# cbass_CBASS_ISC_45820000h register map
Vendor: Texas Instruments
Peripheral module from a debugger description file (folder am62D).
Registers are 32-bit, read-write, reset 0x0 unless marked. A register's access mark holds for its fields unless they carry their own. Offsets are as the file gives them; lines under a group give offsets from that group; [hi:lo] are bit positions; {n}, {i} and the like mark numbered series; 'fields as' and 'values as' point back to an identical list; <NAME> marks a mode.

## cbass_isc (part 1 of 2)
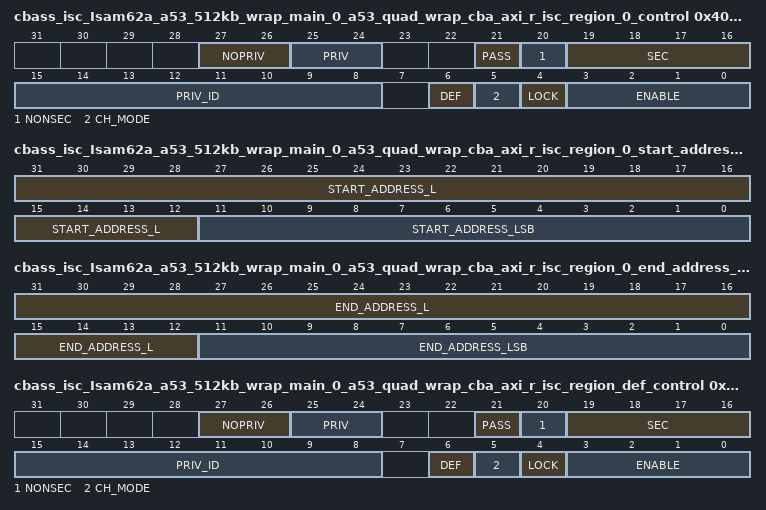
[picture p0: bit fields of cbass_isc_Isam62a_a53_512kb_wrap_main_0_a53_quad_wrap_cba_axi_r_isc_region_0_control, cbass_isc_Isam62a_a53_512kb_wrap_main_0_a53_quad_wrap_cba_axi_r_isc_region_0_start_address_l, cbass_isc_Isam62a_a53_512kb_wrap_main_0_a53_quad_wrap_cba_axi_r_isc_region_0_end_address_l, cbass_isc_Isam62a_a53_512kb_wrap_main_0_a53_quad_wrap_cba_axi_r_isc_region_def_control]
0x400 cbass_isc_Isam62a_a53_512kb_wrap_main_0_a53_quad_wrap_cba_axi_r_isc_region_0_control access not given reset 0x400 — The ISC Region 0 Control Register defines the control fields for the master Isam62a_a53_512kb_wrap_main_0.a53_quad_wrap_cba_axi_r region 0 ISC.
  [27:26] NOPRIV rw — Clear output priv attribute. If each bit is set then the outgoing priv bit is cleared. Reset Source: domain_default_rst_mod_g_rst_n
  [25:24] PRIV rw — Set outgoing priv attribute. If each bit is set then the outgoing priv bit is set. Reset Source: domain_default_rst_mod_g_rst_n
  [21] PASS rw — No privID replacement, pass through value. Reset Source: domain_default_rst_mod_g_rst_n
  [20] NONSEC rw — Make outgoing non-secure. Reset Source: domain_default_rst_mod_g_rst_n
  [19:16] SEC rw — Make outgoing secure. A value of 0xA enables, others disable. Reset Source: domain_default_rst_mod_g_rst_n
  [15:8] PRIV_ID rw — Priv ID. Reset Source: domain_default_rst_mod_g_rst_n
  [6] DEF ro — Default region indication. The default region is used when all other regions do not match. Reset Source: domain_default_rst_mod_g_rst_n
  [5] CH_MODE rw — Enable channel mode to match region to a chanid value. Otherwise use address mode to match region to an address range. Reset Source: domain_default_rst_mod_g_rst_n
  [4] LOCK — Lock region. Once set the region values cannot be modified. Reset Source: domain_default_rst_mod_g_rst_n (access R/W1TS)
  [3:0] ENABLE rw — Enable region. A value of 0xA enables, others disable. Reset Source: domain_default_rst_mod_g_rst_n
0x410 cbass_isc_Isam62a_a53_512kb_wrap_main_0_a53_quad_wrap_cba_axi_r_isc_region_0_start_address_l — The ISC Region 0 Start Address Low Register defines the start address bits 31 to 0 for the master Isam62a_a53_512kb_wrap_main_0.a53_quad_wrap_cba_axi_r region 0 ISC.
  [31:12] START_ADDRESS_L — Start address bits 31 to 12. Reset Source: domain_default_rst_mod_g_rst_n
  [11:0] START_ADDRESS_LSB — Start address bits 11 to 0 must be 0 as address must be 4KB aligned in address mode. Can also be channel number in channel mode. Reset Source: domain_default_rst_mod_g_rst_n
0x414 cbass_isc_Isam62a_a53_512kb_wrap_main_0_a53_quad_wrap_cba_axi_r_isc_region_0_start_address_h — The ISC Region 0 Start Address High Register defines the start address bits 47 to 32 for the master Isam62a_a53_512kb_wrap_main_0.a53_quad_wrap_cba_axi_r region 0 ISC.
  [15:0] START_ADDRESS_H — Start address bits 47 to 32. Reset Source: domain_default_rst_mod_g_rst_n
0x418 cbass_isc_Isam62a_a53_512kb_wrap_main_0_a53_quad_wrap_cba_axi_r_isc_region_0_end_address_l access per field reset 0xFFF — The ISC Region 0 End Address Low Register defines the end included address bits 31 to 0 for the master Isam62a_a53_512kb_wrap_main_0.a53_quad_wrap_cba_axi_r region 0 ISC.
  [31:12] END_ADDRESS_L rw — End address bits 31 to 12 to include in the match. Reset Source: domain_default_rst_mod_g_rst_n
  [11:0] END_ADDRESS_LSB ro — End address bits 11 to 0 are forced to Fs as address must be 4KB aligned. Reset Source: domain_default_rst_mod_g_rst_n
0x41C cbass_isc_Isam62a_a53_512kb_wrap_main_0_a53_quad_wrap_cba_axi_r_isc_region_0_end_address_h — The ISC Region 0 End Address High Register defines the end address bits 47 to 32 for the master Isam62a_a53_512kb_wrap_main_0.a53_quad_wrap_cba_axi_r region 0 ISC.
  [15:0] END_ADDRESS_H — End address bits 47 to 32. Reset Source: domain_default_rst_mod_g_rst_n
0x420 cbass_isc_Isam62a_a53_512kb_wrap_main_0_a53_quad_wrap_cba_axi_r_isc_region_def_control access not given reset 0x44A — The ISC Default Region Control Register defines the control fields for the master Isam62a_a53_512kb_wrap_main_0.a53_quad_wrap_cba_axi_r region 1 ISC.
  [27:26] NOPRIV rw — Clear output priv attribute. If each bit is set then the outgoing priv bit is cleared, else the bit is unchanged. Do not set both priv and nopriv for the same bit. Reset Source: domain_default_rst_mod_g_rst_n
  [25:24] PRIV rw — Set outgoing priv attribute. If each bit is set then the outgoing priv bit is set, else the bit is unchanged. Do not set both priv and nopriv for the same bit. Reset Source: domain_default_rst_mod_g_rst_n
  [21] PASS rw — No privID replacement. A value of 1 will pass through privid value. A value of 0 will replace privid with priv_id field value. Reset Source: domain_default_rst_mod_g_rst_n
  [20] NONSEC rw — Make outgoing non-secure. A value of 1 forces secure clear, others do nothing. Do not set both sec and nonsec. Reset Source: domain_default_rst_mod_g_rst_n
  [19:16] SEC rw — Make outgoing secure. A value of 0xA forces secure set, others do nothing. Do not set both sec and nonsec. Reset Source: domain_default_rst_mod_g_rst_n
  [15:8] PRIV_ID rw — Priv ID value to use if pass is 0. Reset Source: domain_default_rst_mod_g_rst_n
  [6] DEF ro — Default region indication. The default region is used when all other regions do not match. Reset Source: domain_default_rst_mod_g_rst_n
  [5] CH_MODE ro — Enable channel mode to match region to a chanid value. Otherwise use address mode to match region to an address range. Reset Source: domain_default_rst_mod_g_rst_n
  [4] LOCK — Lock region. Once set, the region values cannot be modified. Reset Source: domain_default_rst_mod_g_rst_n (access R/W1TS)
  [3:0] ENABLE ro — Enable region. A value of 0xA enables, others disable. Reset Source: domain_default_rst_mod_g_rst_n
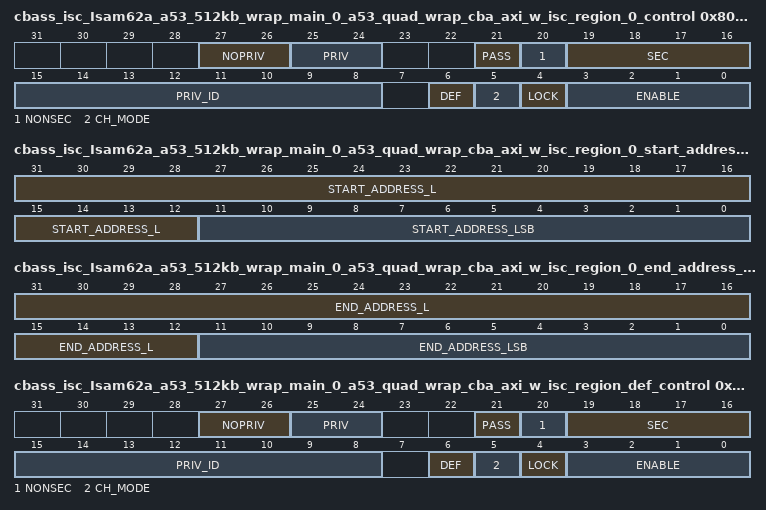
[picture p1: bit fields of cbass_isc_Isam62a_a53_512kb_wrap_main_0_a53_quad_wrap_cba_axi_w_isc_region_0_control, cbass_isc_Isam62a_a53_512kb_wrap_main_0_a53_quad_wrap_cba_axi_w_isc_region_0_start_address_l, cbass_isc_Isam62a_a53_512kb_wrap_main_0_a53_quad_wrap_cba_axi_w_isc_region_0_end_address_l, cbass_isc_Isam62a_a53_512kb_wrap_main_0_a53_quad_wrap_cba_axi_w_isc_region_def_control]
0x800 cbass_isc_Isam62a_a53_512kb_wrap_main_0_a53_quad_wrap_cba_axi_w_isc_region_0_control access not given reset 0x400 — The ISC Region 0 Control Register defines the control fields for the master Isam62a_a53_512kb_wrap_main_0.a53_quad_wrap_cba_axi_w region 0 ISC.
  fields as cbass_isc_Isam62a_a53_512kb_wrap_main_0_a53_quad_wrap_cba_axi_r_isc_region_0_control
0x810 cbass_isc_Isam62a_a53_512kb_wrap_main_0_a53_quad_wrap_cba_axi_w_isc_region_0_start_address_l — The ISC Region 0 Start Address Low Register defines the start address bits 31 to 0 for the master Isam62a_a53_512kb_wrap_main_0.a53_quad_wrap_cba_axi_w region 0 ISC.
  fields as cbass_isc_Isam62a_a53_512kb_wrap_main_0_a53_quad_wrap_cba_axi_r_isc_region_0_start_address_l
0x814 cbass_isc_Isam62a_a53_512kb_wrap_main_0_a53_quad_wrap_cba_axi_w_isc_region_0_start_address_h — The ISC Region 0 Start Address High Register defines the start address bits 47 to 32 for the master Isam62a_a53_512kb_wrap_main_0.a53_quad_wrap_cba_axi_w region 0 ISC.
  fields as cbass_isc_Isam62a_a53_512kb_wrap_main_0_a53_quad_wrap_cba_axi_r_isc_region_0_start_address_h
0x818 cbass_isc_Isam62a_a53_512kb_wrap_main_0_a53_quad_wrap_cba_axi_w_isc_region_0_end_address_l access per field reset 0xFFF — The ISC Region 0 End Address Low Register defines the end included address bits 31 to 0 for the master Isam62a_a53_512kb_wrap_main_0.a53_quad_wrap_cba_axi_w region 0 ISC.
  fields as cbass_isc_Isam62a_a53_512kb_wrap_main_0_a53_quad_wrap_cba_axi_r_isc_region_0_end_address_l
0x81C cbass_isc_Isam62a_a53_512kb_wrap_main_0_a53_quad_wrap_cba_axi_w_isc_region_0_end_address_h — The ISC Region 0 End Address High Register defines the end address bits 47 to 32 for the master Isam62a_a53_512kb_wrap_main_0.a53_quad_wrap_cba_axi_w region 0 ISC.
  fields as cbass_isc_Isam62a_a53_512kb_wrap_main_0_a53_quad_wrap_cba_axi_r_isc_region_0_end_address_h
0x820 cbass_isc_Isam62a_a53_512kb_wrap_main_0_a53_quad_wrap_cba_axi_w_isc_region_def_control access not given reset 0x44A — The ISC Default Region Control Register defines the control fields for the master Isam62a_a53_512kb_wrap_main_0.a53_quad_wrap_cba_axi_w region 1 ISC.
  fields as cbass_isc_Isam62a_a53_512kb_wrap_main_0_a53_quad_wrap_cba_axi_r_isc_region_def_control
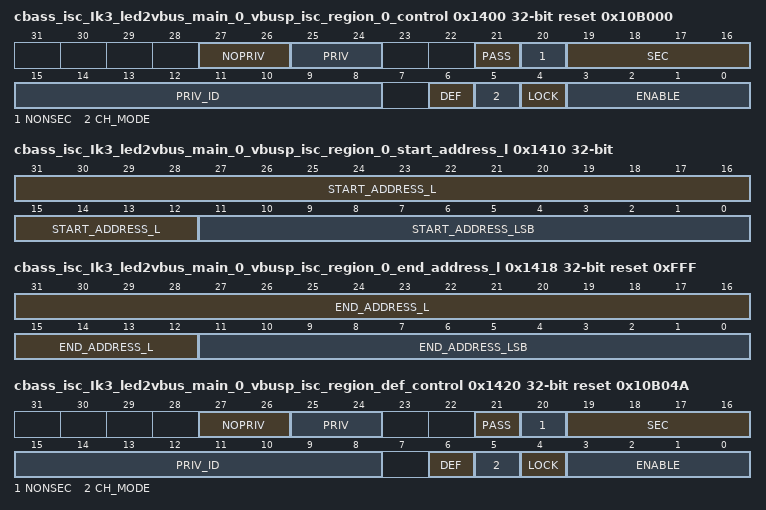
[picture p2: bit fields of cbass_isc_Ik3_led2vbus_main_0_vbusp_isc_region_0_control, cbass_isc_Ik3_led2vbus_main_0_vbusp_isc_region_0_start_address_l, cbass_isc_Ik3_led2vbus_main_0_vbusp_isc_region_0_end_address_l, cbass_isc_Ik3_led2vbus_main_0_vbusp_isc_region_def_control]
0x1400 cbass_isc_Ik3_led2vbus_main_0_vbusp_isc_region_0_control access not given reset 0x10B000 — The ISC Region 0 Control Register defines the control fields for the master Ik3_led2vbus_main_0.vbusp region 0 ISC.
  fields as cbass_isc_Isam62a_a53_512kb_wrap_main_0_a53_quad_wrap_cba_axi_r_isc_region_0_control
0x1410 cbass_isc_Ik3_led2vbus_main_0_vbusp_isc_region_0_start_address_l — The ISC Region 0 Start Address Low Register defines the start address bits 31 to 0 for the master Ik3_led2vbus_main_0.vbusp region 0 ISC.
  fields as cbass_isc_Isam62a_a53_512kb_wrap_main_0_a53_quad_wrap_cba_axi_r_isc_region_0_start_address_l
0x1414 cbass_isc_Ik3_led2vbus_main_0_vbusp_isc_region_0_start_address_h — The ISC Region 0 Start Address High Register defines the start address bits 47 to 32 for the master Ik3_led2vbus_main_0.vbusp region 0 ISC.
  fields as cbass_isc_Isam62a_a53_512kb_wrap_main_0_a53_quad_wrap_cba_axi_r_isc_region_0_start_address_h
0x1418 cbass_isc_Ik3_led2vbus_main_0_vbusp_isc_region_0_end_address_l access per field reset 0xFFF — The ISC Region 0 End Address Low Register defines the end included address bits 31 to 0 for the master Ik3_led2vbus_main_0.vbusp region 0 ISC.
  fields as cbass_isc_Isam62a_a53_512kb_wrap_main_0_a53_quad_wrap_cba_axi_r_isc_region_0_end_address_l
0x141C cbass_isc_Ik3_led2vbus_main_0_vbusp_isc_region_0_end_address_h — The ISC Region 0 End Address High Register defines the end address bits 47 to 32 for the master Ik3_led2vbus_main_0.vbusp region 0 ISC.
  fields as cbass_isc_Isam62a_a53_512kb_wrap_main_0_a53_quad_wrap_cba_axi_r_isc_region_0_end_address_h
0x1420 cbass_isc_Ik3_led2vbus_main_0_vbusp_isc_region_def_control access not given reset 0x10B04A — The ISC Default Region Control Register defines the control fields for the master Ik3_led2vbus_main_0.vbusp region 1 ISC.
  fields as cbass_isc_Isam62a_a53_512kb_wrap_main_0_a53_quad_wrap_cba_axi_r_isc_region_def_control
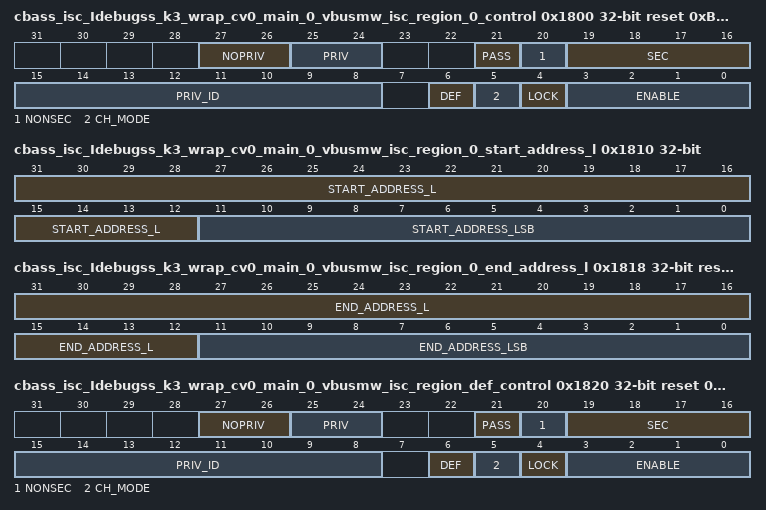
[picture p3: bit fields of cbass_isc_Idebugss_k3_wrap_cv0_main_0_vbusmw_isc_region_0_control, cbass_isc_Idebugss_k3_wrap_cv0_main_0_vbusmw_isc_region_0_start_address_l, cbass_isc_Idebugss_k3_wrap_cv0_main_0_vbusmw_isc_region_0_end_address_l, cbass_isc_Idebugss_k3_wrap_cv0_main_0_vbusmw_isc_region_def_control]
0x1800 cbass_isc_Idebugss_k3_wrap_cv0_main_0_vbusmw_isc_region_0_control access not given reset 0xB100 — The ISC Region 0 Control Register defines the control fields for the master Idebugss_k3_wrap_cv0_main_0.vbusmw region 0 ISC.
  fields as cbass_isc_Isam62a_a53_512kb_wrap_main_0_a53_quad_wrap_cba_axi_r_isc_region_0_control
0x1810 cbass_isc_Idebugss_k3_wrap_cv0_main_0_vbusmw_isc_region_0_start_address_l — The ISC Region 0 Start Address Low Register defines the start address bits 31 to 0 for the master Idebugss_k3_wrap_cv0_main_0.vbusmw region 0 ISC.
  fields as cbass_isc_Isam62a_a53_512kb_wrap_main_0_a53_quad_wrap_cba_axi_r_isc_region_0_start_address_l
0x1814 cbass_isc_Idebugss_k3_wrap_cv0_main_0_vbusmw_isc_region_0_start_address_h — The ISC Region 0 Start Address High Register defines the start address bits 47 to 32 for the master Idebugss_k3_wrap_cv0_main_0.vbusmw region 0 ISC.
  fields as cbass_isc_Isam62a_a53_512kb_wrap_main_0_a53_quad_wrap_cba_axi_r_isc_region_0_start_address_h
0x1818 cbass_isc_Idebugss_k3_wrap_cv0_main_0_vbusmw_isc_region_0_end_address_l access per field reset 0xFFF — The ISC Region 0 End Address Low Register defines the end included address bits 31 to 0 for the master Idebugss_k3_wrap_cv0_main_0.vbusmw region 0 ISC.
  fields as cbass_isc_Isam62a_a53_512kb_wrap_main_0_a53_quad_wrap_cba_axi_r_isc_region_0_end_address_l
0x181C cbass_isc_Idebugss_k3_wrap_cv0_main_0_vbusmw_isc_region_0_end_address_h — The ISC Region 0 End Address High Register defines the end address bits 47 to 32 for the master Idebugss_k3_wrap_cv0_main_0.vbusmw region 0 ISC.
  fields as cbass_isc_Isam62a_a53_512kb_wrap_main_0_a53_quad_wrap_cba_axi_r_isc_region_0_end_address_h
0x1820 cbass_isc_Idebugss_k3_wrap_cv0_main_0_vbusmw_isc_region_def_control access not given reset 0xB14A — The ISC Default Region Control Register defines the control fields for the master Idebugss_k3_wrap_cv0_main_0.vbusmw region 1 ISC.
  fields as cbass_isc_Isam62a_a53_512kb_wrap_main_0_a53_quad_wrap_cba_axi_r_isc_region_def_control
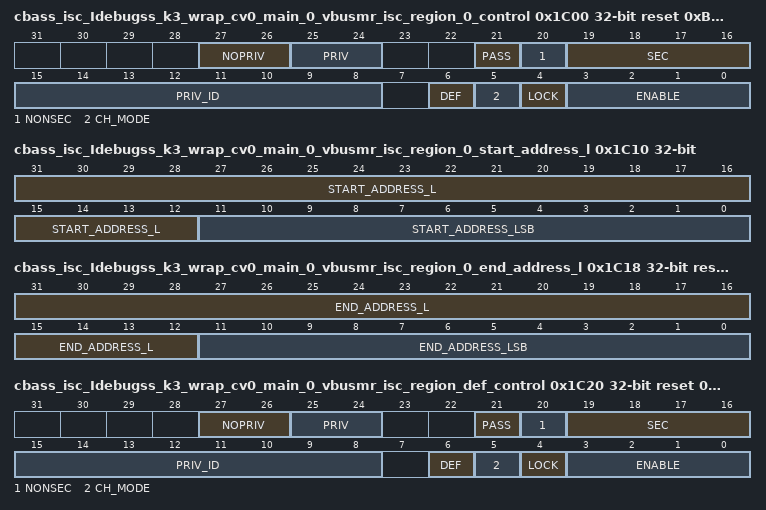
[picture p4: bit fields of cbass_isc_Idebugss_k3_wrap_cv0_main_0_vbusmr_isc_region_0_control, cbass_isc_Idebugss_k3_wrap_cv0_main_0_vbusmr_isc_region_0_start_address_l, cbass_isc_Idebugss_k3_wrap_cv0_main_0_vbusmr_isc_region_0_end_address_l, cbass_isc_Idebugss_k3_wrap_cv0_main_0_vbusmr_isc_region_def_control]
0x1C00 cbass_isc_Idebugss_k3_wrap_cv0_main_0_vbusmr_isc_region_0_control access not given reset 0xB100 — The ISC Region 0 Control Register defines the control fields for the master Idebugss_k3_wrap_cv0_main_0.vbusmr region 0 ISC.
  fields as cbass_isc_Isam62a_a53_512kb_wrap_main_0_a53_quad_wrap_cba_axi_r_isc_region_0_control
0x1C10 cbass_isc_Idebugss_k3_wrap_cv0_main_0_vbusmr_isc_region_0_start_address_l — The ISC Region 0 Start Address Low Register defines the start address bits 31 to 0 for the master Idebugss_k3_wrap_cv0_main_0.vbusmr region 0 ISC.
  fields as cbass_isc_Isam62a_a53_512kb_wrap_main_0_a53_quad_wrap_cba_axi_r_isc_region_0_start_address_l
0x1C14 cbass_isc_Idebugss_k3_wrap_cv0_main_0_vbusmr_isc_region_0_start_address_h — The ISC Region 0 Start Address High Register defines the start address bits 47 to 32 for the master Idebugss_k3_wrap_cv0_main_0.vbusmr region 0 ISC.
  fields as cbass_isc_Isam62a_a53_512kb_wrap_main_0_a53_quad_wrap_cba_axi_r_isc_region_0_start_address_h
0x1C18 cbass_isc_Idebugss_k3_wrap_cv0_main_0_vbusmr_isc_region_0_end_address_l access per field reset 0xFFF — The ISC Region 0 End Address Low Register defines the end included address bits 31 to 0 for the master Idebugss_k3_wrap_cv0_main_0.vbusmr region 0 ISC.
  fields as cbass_isc_Isam62a_a53_512kb_wrap_main_0_a53_quad_wrap_cba_axi_r_isc_region_0_end_address_l
0x1C1C cbass_isc_Idebugss_k3_wrap_cv0_main_0_vbusmr_isc_region_0_end_address_h — The ISC Region 0 End Address High Register defines the end address bits 47 to 32 for the master Idebugss_k3_wrap_cv0_main_0.vbusmr region 0 ISC.
  fields as cbass_isc_Isam62a_a53_512kb_wrap_main_0_a53_quad_wrap_cba_axi_r_isc_region_0_end_address_h
0x1C20 cbass_isc_Idebugss_k3_wrap_cv0_main_0_vbusmr_isc_region_def_control access not given reset 0xB14A — The ISC Default Region Control Register defines the control fields for the master Idebugss_k3_wrap_cv0_main_0.vbusmr region 1 ISC.
  fields as cbass_isc_Isam62a_a53_512kb_wrap_main_0_a53_quad_wrap_cba_axi_r_isc_region_def_control
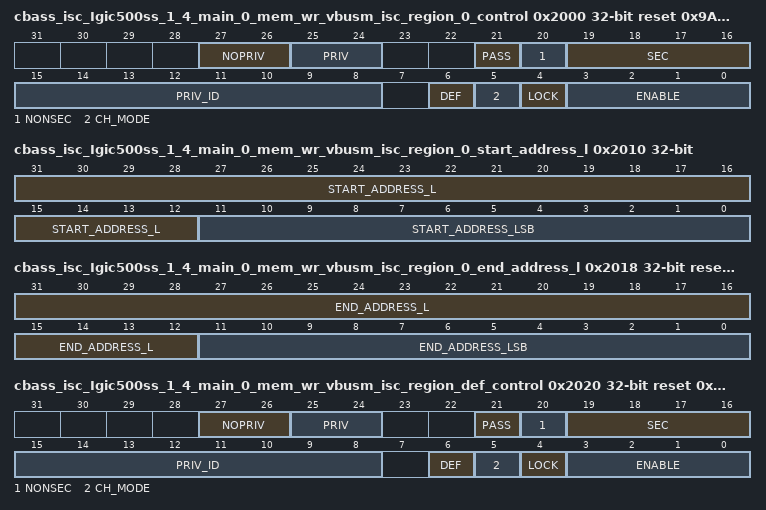
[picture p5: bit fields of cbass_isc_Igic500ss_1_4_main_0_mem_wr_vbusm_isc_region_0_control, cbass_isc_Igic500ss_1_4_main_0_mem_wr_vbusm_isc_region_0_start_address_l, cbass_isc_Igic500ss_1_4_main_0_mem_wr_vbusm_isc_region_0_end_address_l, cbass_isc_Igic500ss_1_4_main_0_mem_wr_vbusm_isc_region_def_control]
0x2000 cbass_isc_Igic500ss_1_4_main_0_mem_wr_vbusm_isc_region_0_control access not given reset 0x9A00 — The ISC Region 0 Control Register defines the control fields for the master Igic500ss_1_4_main_0.mem_wr_vbusm region 0 ISC.
  fields as cbass_isc_Isam62a_a53_512kb_wrap_main_0_a53_quad_wrap_cba_axi_r_isc_region_0_control
0x2010 cbass_isc_Igic500ss_1_4_main_0_mem_wr_vbusm_isc_region_0_start_address_l — The ISC Region 0 Start Address Low Register defines the start address bits 31 to 0 for the master Igic500ss_1_4_main_0.mem_wr_vbusm region 0 ISC.
  fields as cbass_isc_Isam62a_a53_512kb_wrap_main_0_a53_quad_wrap_cba_axi_r_isc_region_0_start_address_l
0x2014 cbass_isc_Igic500ss_1_4_main_0_mem_wr_vbusm_isc_region_0_start_address_h — The ISC Region 0 Start Address High Register defines the start address bits 47 to 32 for the master Igic500ss_1_4_main_0.mem_wr_vbusm region 0 ISC.
  fields as cbass_isc_Isam62a_a53_512kb_wrap_main_0_a53_quad_wrap_cba_axi_r_isc_region_0_start_address_h
0x2018 cbass_isc_Igic500ss_1_4_main_0_mem_wr_vbusm_isc_region_0_end_address_l access per field reset 0xFFF — The ISC Region 0 End Address Low Register defines the end included address bits 31 to 0 for the master Igic500ss_1_4_main_0.mem_wr_vbusm region 0 ISC.
  fields as cbass_isc_Isam62a_a53_512kb_wrap_main_0_a53_quad_wrap_cba_axi_r_isc_region_0_end_address_l
0x201C cbass_isc_Igic500ss_1_4_main_0_mem_wr_vbusm_isc_region_0_end_address_h — The ISC Region 0 End Address High Register defines the end address bits 47 to 32 for the master Igic500ss_1_4_main_0.mem_wr_vbusm region 0 ISC.
  fields as cbass_isc_Isam62a_a53_512kb_wrap_main_0_a53_quad_wrap_cba_axi_r_isc_region_0_end_address_h
0x2020 cbass_isc_Igic500ss_1_4_main_0_mem_wr_vbusm_isc_region_def_control access not given reset 0x9A4A — The ISC Default Region Control Register defines the control fields for the master Igic500ss_1_4_main_0.mem_wr_vbusm region 1 ISC.
  fields as cbass_isc_Isam62a_a53_512kb_wrap_main_0_a53_quad_wrap_cba_axi_r_isc_region_def_control
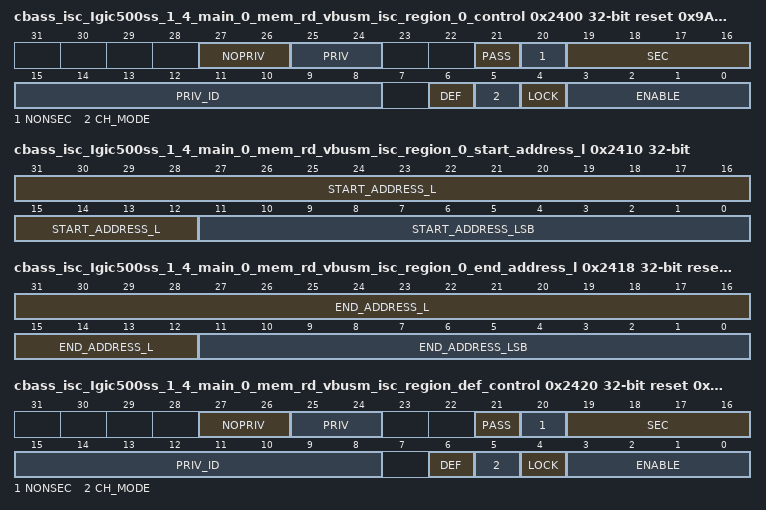
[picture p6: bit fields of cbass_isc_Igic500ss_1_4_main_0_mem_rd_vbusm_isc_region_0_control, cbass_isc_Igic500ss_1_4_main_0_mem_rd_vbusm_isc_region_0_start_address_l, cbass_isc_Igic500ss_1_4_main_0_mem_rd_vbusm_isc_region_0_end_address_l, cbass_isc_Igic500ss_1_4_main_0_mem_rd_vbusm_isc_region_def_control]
0x2400 cbass_isc_Igic500ss_1_4_main_0_mem_rd_vbusm_isc_region_0_control access not given reset 0x9A00 — The ISC Region 0 Control Register defines the control fields for the master Igic500ss_1_4_main_0.mem_rd_vbusm region 0 ISC.
  fields as cbass_isc_Isam62a_a53_512kb_wrap_main_0_a53_quad_wrap_cba_axi_r_isc_region_0_control
0x2410 cbass_isc_Igic500ss_1_4_main_0_mem_rd_vbusm_isc_region_0_start_address_l — The ISC Region 0 Start Address Low Register defines the start address bits 31 to 0 for the master Igic500ss_1_4_main_0.mem_rd_vbusm region 0 ISC.
  fields as cbass_isc_Isam62a_a53_512kb_wrap_main_0_a53_quad_wrap_cba_axi_r_isc_region_0_start_address_l
0x2414 cbass_isc_Igic500ss_1_4_main_0_mem_rd_vbusm_isc_region_0_start_address_h — The ISC Region 0 Start Address High Register defines the start address bits 47 to 32 for the master Igic500ss_1_4_main_0.mem_rd_vbusm region 0 ISC.
  fields as cbass_isc_Isam62a_a53_512kb_wrap_main_0_a53_quad_wrap_cba_axi_r_isc_region_0_start_address_h
0x2418 cbass_isc_Igic500ss_1_4_main_0_mem_rd_vbusm_isc_region_0_end_address_l access per field reset 0xFFF — The ISC Region 0 End Address Low Register defines the end included address bits 31 to 0 for the master Igic500ss_1_4_main_0.mem_rd_vbusm region 0 ISC.
  fields as cbass_isc_Isam62a_a53_512kb_wrap_main_0_a53_quad_wrap_cba_axi_r_isc_region_0_end_address_l
0x241C cbass_isc_Igic500ss_1_4_main_0_mem_rd_vbusm_isc_region_0_end_address_h — The ISC Region 0 End Address High Register defines the end address bits 47 to 32 for the master Igic500ss_1_4_main_0.mem_rd_vbusm region 0 ISC.
  fields as cbass_isc_Isam62a_a53_512kb_wrap_main_0_a53_quad_wrap_cba_axi_r_isc_region_0_end_address_h
0x2420 cbass_isc_Igic500ss_1_4_main_0_mem_rd_vbusm_isc_region_def_control access not given reset 0x9A4A — The ISC Default Region Control Register defines the control fields for the master Igic500ss_1_4_main_0.mem_rd_vbusm region 1 ISC.
  fields as cbass_isc_Isam62a_a53_512kb_wrap_main_0_a53_quad_wrap_cba_axi_r_isc_region_def_control
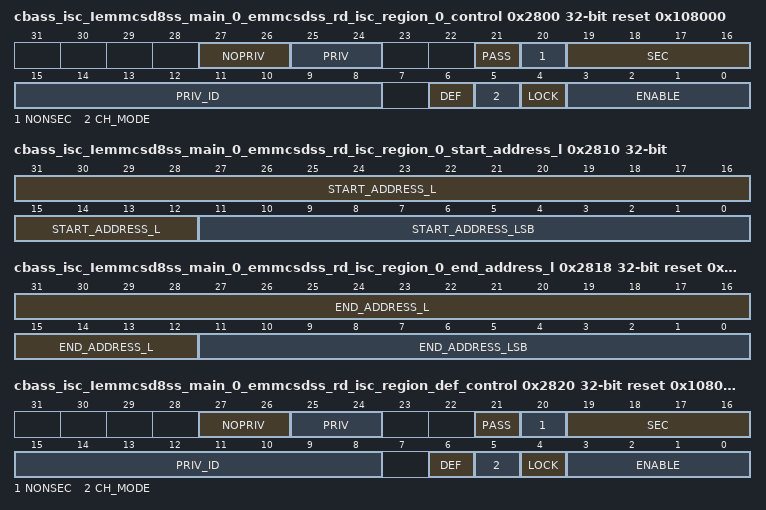
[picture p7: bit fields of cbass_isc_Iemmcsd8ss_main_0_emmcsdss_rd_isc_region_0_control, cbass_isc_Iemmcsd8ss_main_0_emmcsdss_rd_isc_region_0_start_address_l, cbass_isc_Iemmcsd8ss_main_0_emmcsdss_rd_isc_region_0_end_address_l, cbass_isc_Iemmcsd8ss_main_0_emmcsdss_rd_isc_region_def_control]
0x2800 cbass_isc_Iemmcsd8ss_main_0_emmcsdss_rd_isc_region_0_control access not given reset 0x108000 — The ISC Region 0 Control Register defines the control fields for the master Iemmcsd8ss_main_0.emmcsdss_rd region 0 ISC.
  fields as cbass_isc_Isam62a_a53_512kb_wrap_main_0_a53_quad_wrap_cba_axi_r_isc_region_0_control
0x2810 cbass_isc_Iemmcsd8ss_main_0_emmcsdss_rd_isc_region_0_start_address_l — The ISC Region 0 Start Address Low Register defines the start address bits 31 to 0 for the master Iemmcsd8ss_main_0.emmcsdss_rd region 0 ISC.
  fields as cbass_isc_Isam62a_a53_512kb_wrap_main_0_a53_quad_wrap_cba_axi_r_isc_region_0_start_address_l
0x2814 cbass_isc_Iemmcsd8ss_main_0_emmcsdss_rd_isc_region_0_start_address_h — The ISC Region 0 Start Address High Register defines the start address bits 47 to 32 for the master Iemmcsd8ss_main_0.emmcsdss_rd region 0 ISC.
  fields as cbass_isc_Isam62a_a53_512kb_wrap_main_0_a53_quad_wrap_cba_axi_r_isc_region_0_start_address_h
0x2818 cbass_isc_Iemmcsd8ss_main_0_emmcsdss_rd_isc_region_0_end_address_l access per field reset 0xFFF — The ISC Region 0 End Address Low Register defines the end included address bits 31 to 0 for the master Iemmcsd8ss_main_0.emmcsdss_rd region 0 ISC.
  fields as cbass_isc_Isam62a_a53_512kb_wrap_main_0_a53_quad_wrap_cba_axi_r_isc_region_0_end_address_l
0x281C cbass_isc_Iemmcsd8ss_main_0_emmcsdss_rd_isc_region_0_end_address_h — The ISC Region 0 End Address High Register defines the end address bits 47 to 32 for the master Iemmcsd8ss_main_0.emmcsdss_rd region 0 ISC.
  fields as cbass_isc_Isam62a_a53_512kb_wrap_main_0_a53_quad_wrap_cba_axi_r_isc_region_0_end_address_h
0x2820 cbass_isc_Iemmcsd8ss_main_0_emmcsdss_rd_isc_region_def_control access not given reset 0x10804A — The ISC Default Region Control Register defines the control fields for the master Iemmcsd8ss_main_0.emmcsdss_rd region 1 ISC.
  fields as cbass_isc_Isam62a_a53_512kb_wrap_main_0_a53_quad_wrap_cba_axi_r_isc_region_def_control
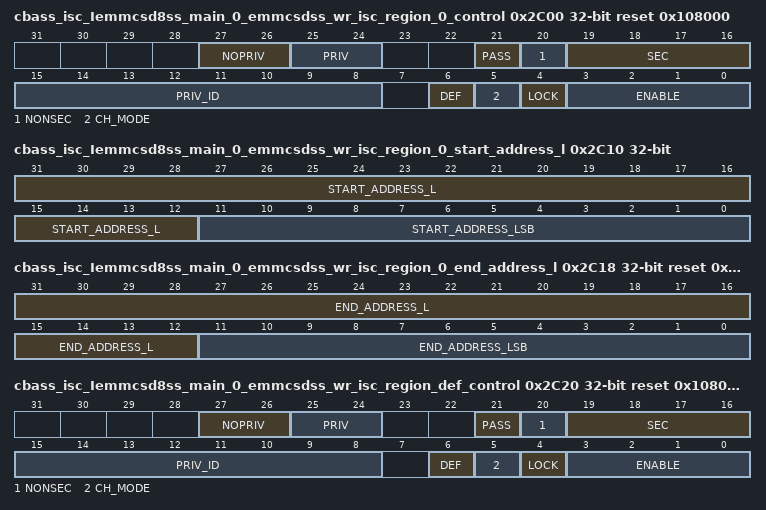
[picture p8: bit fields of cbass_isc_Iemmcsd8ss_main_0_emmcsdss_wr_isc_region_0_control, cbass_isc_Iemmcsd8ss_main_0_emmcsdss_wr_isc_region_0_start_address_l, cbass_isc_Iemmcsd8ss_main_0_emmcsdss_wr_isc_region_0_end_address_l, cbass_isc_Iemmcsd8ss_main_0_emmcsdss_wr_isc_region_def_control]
0x2C00 cbass_isc_Iemmcsd8ss_main_0_emmcsdss_wr_isc_region_0_control access not given reset 0x108000 — The ISC Region 0 Control Register defines the control fields for the master Iemmcsd8ss_main_0.emmcsdss_wr region 0 ISC.
  fields as cbass_isc_Isam62a_a53_512kb_wrap_main_0_a53_quad_wrap_cba_axi_r_isc_region_0_control
0x2C10 cbass_isc_Iemmcsd8ss_main_0_emmcsdss_wr_isc_region_0_start_address_l — The ISC Region 0 Start Address Low Register defines the start address bits 31 to 0 for the master Iemmcsd8ss_main_0.emmcsdss_wr region 0 ISC.
  fields as cbass_isc_Isam62a_a53_512kb_wrap_main_0_a53_quad_wrap_cba_axi_r_isc_region_0_start_address_l
0x2C14 cbass_isc_Iemmcsd8ss_main_0_emmcsdss_wr_isc_region_0_start_address_h — The ISC Region 0 Start Address High Register defines the start address bits 47 to 32 for the master Iemmcsd8ss_main_0.emmcsdss_wr region 0 ISC.
  fields as cbass_isc_Isam62a_a53_512kb_wrap_main_0_a53_quad_wrap_cba_axi_r_isc_region_0_start_address_h
0x2C18 cbass_isc_Iemmcsd8ss_main_0_emmcsdss_wr_isc_region_0_end_address_l access per field reset 0xFFF — The ISC Region 0 End Address Low Register defines the end included address bits 31 to 0 for the master Iemmcsd8ss_main_0.emmcsdss_wr region 0 ISC.
  fields as cbass_isc_Isam62a_a53_512kb_wrap_main_0_a53_quad_wrap_cba_axi_r_isc_region_0_end_address_l
0x2C1C cbass_isc_Iemmcsd8ss_main_0_emmcsdss_wr_isc_region_0_end_address_h — The ISC Region 0 End Address High Register defines the end address bits 47 to 32 for the master Iemmcsd8ss_main_0.emmcsdss_wr region 0 ISC.
  fields as cbass_isc_Isam62a_a53_512kb_wrap_main_0_a53_quad_wrap_cba_axi_r_isc_region_0_end_address_h
0x2C20 cbass_isc_Iemmcsd8ss_main_0_emmcsdss_wr_isc_region_def_control access not given reset 0x10804A — The ISC Default Region Control Register defines the control fields for the master Iemmcsd8ss_main_0.emmcsdss_wr region 1 ISC.
  fields as cbass_isc_Isam62a_a53_512kb_wrap_main_0_a53_quad_wrap_cba_axi_r_isc_region_def_control
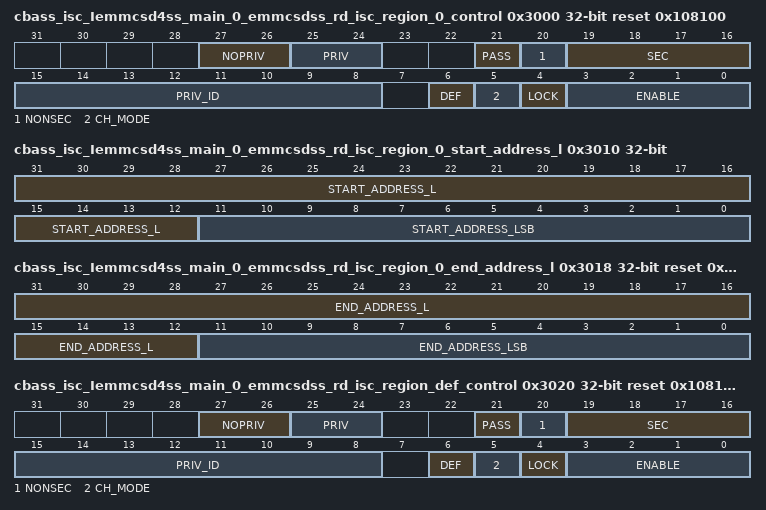
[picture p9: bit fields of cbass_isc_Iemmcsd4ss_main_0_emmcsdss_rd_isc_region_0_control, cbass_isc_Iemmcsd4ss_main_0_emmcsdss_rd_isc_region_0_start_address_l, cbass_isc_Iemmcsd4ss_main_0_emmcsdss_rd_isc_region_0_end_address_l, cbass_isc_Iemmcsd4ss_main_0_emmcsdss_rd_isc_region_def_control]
0x3000 cbass_isc_Iemmcsd4ss_main_0_emmcsdss_rd_isc_region_0_control access not given reset 0x108100 — The ISC Region 0 Control Register defines the control fields for the master Iemmcsd4ss_main_0.emmcsdss_rd region 0 ISC.
  fields as cbass_isc_Isam62a_a53_512kb_wrap_main_0_a53_quad_wrap_cba_axi_r_isc_region_0_control
0x3010 cbass_isc_Iemmcsd4ss_main_0_emmcsdss_rd_isc_region_0_start_address_l — The ISC Region 0 Start Address Low Register defines the start address bits 31 to 0 for the master Iemmcsd4ss_main_0.emmcsdss_rd region 0 ISC.
  fields as cbass_isc_Isam62a_a53_512kb_wrap_main_0_a53_quad_wrap_cba_axi_r_isc_region_0_start_address_l
0x3014 cbass_isc_Iemmcsd4ss_main_0_emmcsdss_rd_isc_region_0_start_address_h — The ISC Region 0 Start Address High Register defines the start address bits 47 to 32 for the master Iemmcsd4ss_main_0.emmcsdss_rd region 0 ISC.
  fields as cbass_isc_Isam62a_a53_512kb_wrap_main_0_a53_quad_wrap_cba_axi_r_isc_region_0_start_address_h
0x3018 cbass_isc_Iemmcsd4ss_main_0_emmcsdss_rd_isc_region_0_end_address_l access per field reset 0xFFF — The ISC Region 0 End Address Low Register defines the end included address bits 31 to 0 for the master Iemmcsd4ss_main_0.emmcsdss_rd region 0 ISC.
  fields as cbass_isc_Isam62a_a53_512kb_wrap_main_0_a53_quad_wrap_cba_axi_r_isc_region_0_end_address_l
0x301C cbass_isc_Iemmcsd4ss_main_0_emmcsdss_rd_isc_region_0_end_address_h — The ISC Region 0 End Address High Register defines the end address bits 47 to 32 for the master Iemmcsd4ss_main_0.emmcsdss_rd region 0 ISC.
  fields as cbass_isc_Isam62a_a53_512kb_wrap_main_0_a53_quad_wrap_cba_axi_r_isc_region_0_end_address_h
0x3020 cbass_isc_Iemmcsd4ss_main_0_emmcsdss_rd_isc_region_def_control access not given reset 0x10814A — The ISC Default Region Control Register defines the control fields for the master Iemmcsd4ss_main_0.emmcsdss_rd region 1 ISC.
  fields as cbass_isc_Isam62a_a53_512kb_wrap_main_0_a53_quad_wrap_cba_axi_r_isc_region_def_control
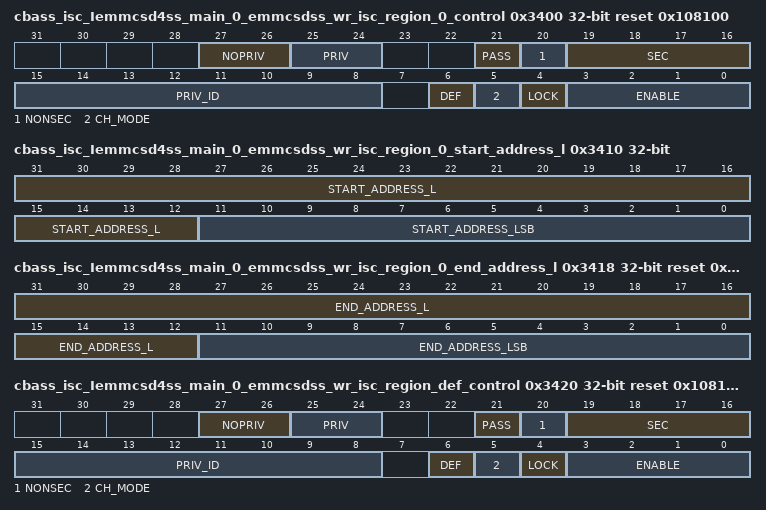
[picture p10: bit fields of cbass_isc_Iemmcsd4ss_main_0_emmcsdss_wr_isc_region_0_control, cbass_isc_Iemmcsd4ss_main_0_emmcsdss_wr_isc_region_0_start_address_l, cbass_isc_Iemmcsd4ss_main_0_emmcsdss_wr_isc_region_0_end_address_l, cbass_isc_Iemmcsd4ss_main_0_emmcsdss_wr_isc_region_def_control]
0x3400 cbass_isc_Iemmcsd4ss_main_0_emmcsdss_wr_isc_region_0_control access not given reset 0x108100 — The ISC Region 0 Control Register defines the control fields for the master Iemmcsd4ss_main_0.emmcsdss_wr region 0 ISC.
  fields as cbass_isc_Isam62a_a53_512kb_wrap_main_0_a53_quad_wrap_cba_axi_r_isc_region_0_control
0x3410 cbass_isc_Iemmcsd4ss_main_0_emmcsdss_wr_isc_region_0_start_address_l — The ISC Region 0 Start Address Low Register defines the start address bits 31 to 0 for the master Iemmcsd4ss_main_0.emmcsdss_wr region 0 ISC.
  fields as cbass_isc_Isam62a_a53_512kb_wrap_main_0_a53_quad_wrap_cba_axi_r_isc_region_0_start_address_l
0x3414 cbass_isc_Iemmcsd4ss_main_0_emmcsdss_wr_isc_region_0_start_address_h — The ISC Region 0 Start Address High Register defines the start address bits 47 to 32 for the master Iemmcsd4ss_main_0.emmcsdss_wr region 0 ISC.
  fields as cbass_isc_Isam62a_a53_512kb_wrap_main_0_a53_quad_wrap_cba_axi_r_isc_region_0_start_address_h
0x3418 cbass_isc_Iemmcsd4ss_main_0_emmcsdss_wr_isc_region_0_end_address_l access per field reset 0xFFF — The ISC Region 0 End Address Low Register defines the end included address bits 31 to 0 for the master Iemmcsd4ss_main_0.emmcsdss_wr region 0 ISC.
  fields as cbass_isc_Isam62a_a53_512kb_wrap_main_0_a53_quad_wrap_cba_axi_r_isc_region_0_end_address_l
0x341C cbass_isc_Iemmcsd4ss_main_0_emmcsdss_wr_isc_region_0_end_address_h — The ISC Region 0 End Address High Register defines the end address bits 47 to 32 for the master Iemmcsd4ss_main_0.emmcsdss_wr region 0 ISC.
  fields as cbass_isc_Isam62a_a53_512kb_wrap_main_0_a53_quad_wrap_cba_axi_r_isc_region_0_end_address_h
0x3420 cbass_isc_Iemmcsd4ss_main_0_emmcsdss_wr_isc_region_def_control access not given reset 0x10814A — The ISC Default Region Control Register defines the control fields for the master Iemmcsd4ss_main_0.emmcsdss_wr region 1 ISC.
  fields as cbass_isc_Isam62a_a53_512kb_wrap_main_0_a53_quad_wrap_cba_axi_r_isc_region_def_control
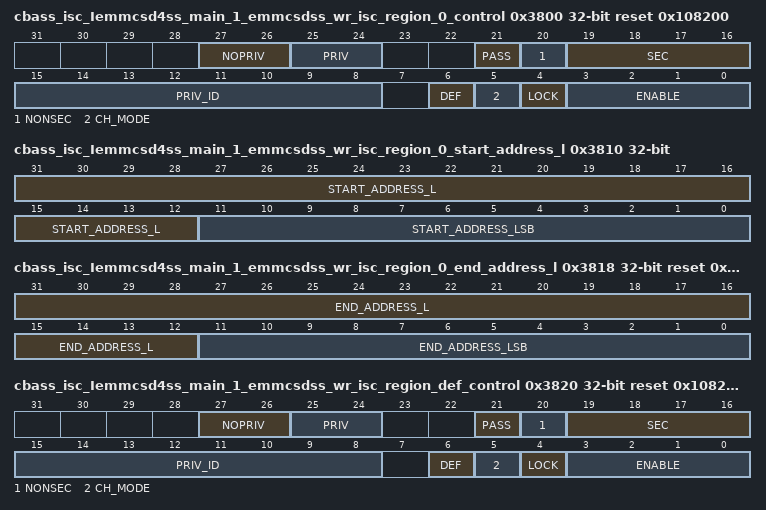
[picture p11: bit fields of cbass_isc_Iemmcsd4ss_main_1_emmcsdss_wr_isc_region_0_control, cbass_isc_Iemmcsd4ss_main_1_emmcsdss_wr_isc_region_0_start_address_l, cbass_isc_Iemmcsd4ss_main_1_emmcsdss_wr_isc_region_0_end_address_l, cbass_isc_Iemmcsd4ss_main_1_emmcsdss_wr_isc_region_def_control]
0x3800 cbass_isc_Iemmcsd4ss_main_1_emmcsdss_wr_isc_region_0_control access not given reset 0x108200 — The ISC Region 0 Control Register defines the control fields for the master Iemmcsd4ss_main_1.emmcsdss_wr region 0 ISC.
  fields as cbass_isc_Isam62a_a53_512kb_wrap_main_0_a53_quad_wrap_cba_axi_r_isc_region_0_control
0x3810 cbass_isc_Iemmcsd4ss_main_1_emmcsdss_wr_isc_region_0_start_address_l — The ISC Region 0 Start Address Low Register defines the start address bits 31 to 0 for the master Iemmcsd4ss_main_1.emmcsdss_wr region 0 ISC.
  fields as cbass_isc_Isam62a_a53_512kb_wrap_main_0_a53_quad_wrap_cba_axi_r_isc_region_0_start_address_l
0x3814 cbass_isc_Iemmcsd4ss_main_1_emmcsdss_wr_isc_region_0_start_address_h — The ISC Region 0 Start Address High Register defines the start address bits 47 to 32 for the master Iemmcsd4ss_main_1.emmcsdss_wr region 0 ISC.
  fields as cbass_isc_Isam62a_a53_512kb_wrap_main_0_a53_quad_wrap_cba_axi_r_isc_region_0_start_address_h
0x3818 cbass_isc_Iemmcsd4ss_main_1_emmcsdss_wr_isc_region_0_end_address_l access per field reset 0xFFF — The ISC Region 0 End Address Low Register defines the end included address bits 31 to 0 for the master Iemmcsd4ss_main_1.emmcsdss_wr region 0 ISC.
  fields as cbass_isc_Isam62a_a53_512kb_wrap_main_0_a53_quad_wrap_cba_axi_r_isc_region_0_end_address_l
0x381C cbass_isc_Iemmcsd4ss_main_1_emmcsdss_wr_isc_region_0_end_address_h — The ISC Region 0 End Address High Register defines the end address bits 47 to 32 for the master Iemmcsd4ss_main_1.emmcsdss_wr region 0 ISC.
  fields as cbass_isc_Isam62a_a53_512kb_wrap_main_0_a53_quad_wrap_cba_axi_r_isc_region_0_end_address_h
0x3820 cbass_isc_Iemmcsd4ss_main_1_emmcsdss_wr_isc_region_def_control access not given reset 0x10824A — The ISC Default Region Control Register defines the control fields for the master Iemmcsd4ss_main_1.emmcsdss_wr region 1 ISC.
  fields as cbass_isc_Isam62a_a53_512kb_wrap_main_0_a53_quad_wrap_cba_axi_r_isc_region_def_control
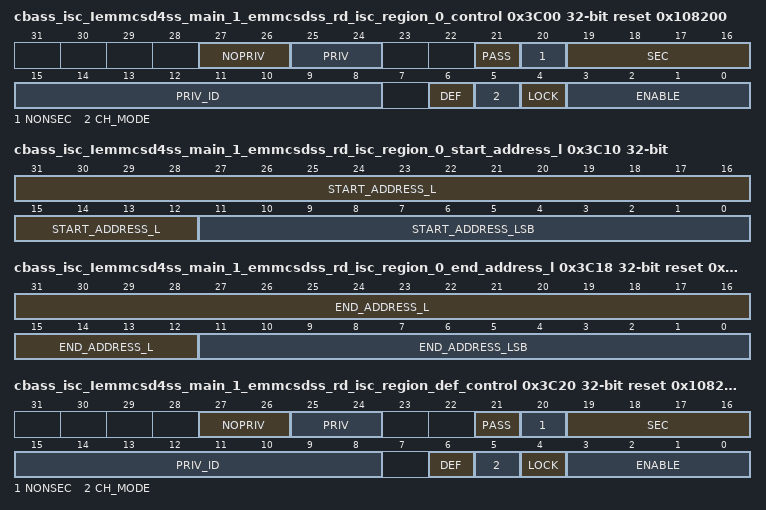
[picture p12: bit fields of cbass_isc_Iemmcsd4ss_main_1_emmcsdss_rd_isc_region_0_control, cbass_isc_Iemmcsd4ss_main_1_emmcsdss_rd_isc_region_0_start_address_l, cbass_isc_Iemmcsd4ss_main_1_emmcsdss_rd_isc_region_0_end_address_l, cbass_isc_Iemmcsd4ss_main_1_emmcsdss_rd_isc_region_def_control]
0x3C00 cbass_isc_Iemmcsd4ss_main_1_emmcsdss_rd_isc_region_0_control access not given reset 0x108200 — The ISC Region 0 Control Register defines the control fields for the master Iemmcsd4ss_main_1.emmcsdss_rd region 0 ISC.
  fields as cbass_isc_Isam62a_a53_512kb_wrap_main_0_a53_quad_wrap_cba_axi_r_isc_region_0_control
0x3C10 cbass_isc_Iemmcsd4ss_main_1_emmcsdss_rd_isc_region_0_start_address_l — The ISC Region 0 Start Address Low Register defines the start address bits 31 to 0 for the master Iemmcsd4ss_main_1.emmcsdss_rd region 0 ISC.
  fields as cbass_isc_Isam62a_a53_512kb_wrap_main_0_a53_quad_wrap_cba_axi_r_isc_region_0_start_address_l
0x3C14 cbass_isc_Iemmcsd4ss_main_1_emmcsdss_rd_isc_region_0_start_address_h — The ISC Region 0 Start Address High Register defines the start address bits 47 to 32 for the master Iemmcsd4ss_main_1.emmcsdss_rd region 0 ISC.
  fields as cbass_isc_Isam62a_a53_512kb_wrap_main_0_a53_quad_wrap_cba_axi_r_isc_region_0_start_address_h
0x3C18 cbass_isc_Iemmcsd4ss_main_1_emmcsdss_rd_isc_region_0_end_address_l access per field reset 0xFFF — The ISC Region 0 End Address Low Register defines the end included address bits 31 to 0 for the master Iemmcsd4ss_main_1.emmcsdss_rd region 0 ISC.
  fields as cbass_isc_Isam62a_a53_512kb_wrap_main_0_a53_quad_wrap_cba_axi_r_isc_region_0_end_address_l
0x3C1C cbass_isc_Iemmcsd4ss_main_1_emmcsdss_rd_isc_region_0_end_address_h — The ISC Region 0 End Address High Register defines the end address bits 47 to 32 for the master Iemmcsd4ss_main_1.emmcsdss_rd region 0 ISC.
  fields as cbass_isc_Isam62a_a53_512kb_wrap_main_0_a53_quad_wrap_cba_axi_r_isc_region_0_end_address_h
0x3C20 cbass_isc_Iemmcsd4ss_main_1_emmcsdss_rd_isc_region_def_control access not given reset 0x10824A — The ISC Default Region Control Register defines the control fields for the master Iemmcsd4ss_main_1.emmcsdss_rd region 1 ISC.
  fields as cbass_isc_Isam62a_a53_512kb_wrap_main_0_a53_quad_wrap_cba_axi_r_isc_region_def_control
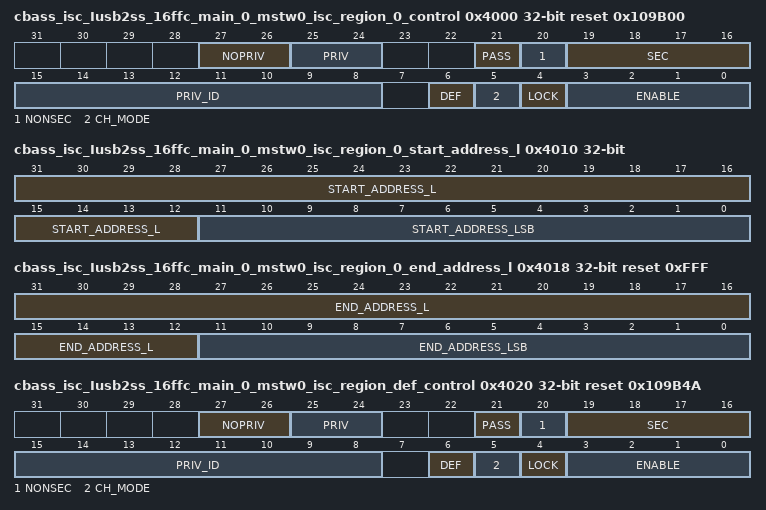
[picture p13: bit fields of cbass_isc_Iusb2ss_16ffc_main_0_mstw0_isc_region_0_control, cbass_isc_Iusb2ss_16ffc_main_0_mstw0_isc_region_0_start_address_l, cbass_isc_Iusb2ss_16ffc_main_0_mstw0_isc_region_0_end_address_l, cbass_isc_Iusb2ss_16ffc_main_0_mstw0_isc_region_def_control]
0x4000 cbass_isc_Iusb2ss_16ffc_main_0_mstw0_isc_region_0_control access not given reset 0x109B00 — The ISC Region 0 Control Register defines the control fields for the master Iusb2ss_16ffc_main_0.mstw0 region 0 ISC.
  fields as cbass_isc_Isam62a_a53_512kb_wrap_main_0_a53_quad_wrap_cba_axi_r_isc_region_0_control
0x4010 cbass_isc_Iusb2ss_16ffc_main_0_mstw0_isc_region_0_start_address_l — The ISC Region 0 Start Address Low Register defines the start address bits 31 to 0 for the master Iusb2ss_16ffc_main_0.mstw0 region 0 ISC.
  fields as cbass_isc_Isam62a_a53_512kb_wrap_main_0_a53_quad_wrap_cba_axi_r_isc_region_0_start_address_l
0x4014 cbass_isc_Iusb2ss_16ffc_main_0_mstw0_isc_region_0_start_address_h — The ISC Region 0 Start Address High Register defines the start address bits 47 to 32 for the master Iusb2ss_16ffc_main_0.mstw0 region 0 ISC.
  fields as cbass_isc_Isam62a_a53_512kb_wrap_main_0_a53_quad_wrap_cba_axi_r_isc_region_0_start_address_h
0x4018 cbass_isc_Iusb2ss_16ffc_main_0_mstw0_isc_region_0_end_address_l access per field reset 0xFFF — The ISC Region 0 End Address Low Register defines the end included address bits 31 to 0 for the master Iusb2ss_16ffc_main_0.mstw0 region 0 ISC.
  fields as cbass_isc_Isam62a_a53_512kb_wrap_main_0_a53_quad_wrap_cba_axi_r_isc_region_0_end_address_l
0x401C cbass_isc_Iusb2ss_16ffc_main_0_mstw0_isc_region_0_end_address_h — The ISC Region 0 End Address High Register defines the end address bits 47 to 32 for the master Iusb2ss_16ffc_main_0.mstw0 region 0 ISC.
  fields as cbass_isc_Isam62a_a53_512kb_wrap_main_0_a53_quad_wrap_cba_axi_r_isc_region_0_end_address_h
0x4020 cbass_isc_Iusb2ss_16ffc_main_0_mstw0_isc_region_def_control access not given reset 0x109B4A — The ISC Default Region Control Register defines the control fields for the master Iusb2ss_16ffc_main_0.mstw0 region 1 ISC.
  fields as cbass_isc_Isam62a_a53_512kb_wrap_main_0_a53_quad_wrap_cba_axi_r_isc_region_def_control
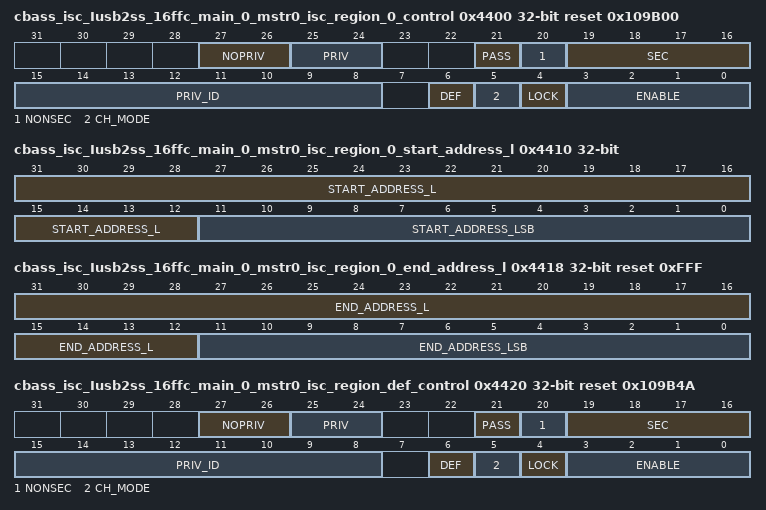
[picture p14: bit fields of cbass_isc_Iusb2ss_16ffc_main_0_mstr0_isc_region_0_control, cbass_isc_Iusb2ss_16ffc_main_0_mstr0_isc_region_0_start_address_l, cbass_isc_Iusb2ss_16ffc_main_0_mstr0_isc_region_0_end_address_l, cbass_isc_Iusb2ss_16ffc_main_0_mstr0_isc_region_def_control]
0x4400 cbass_isc_Iusb2ss_16ffc_main_0_mstr0_isc_region_0_control access not given reset 0x109B00 — The ISC Region 0 Control Register defines the control fields for the master Iusb2ss_16ffc_main_0.mstr0 region 0 ISC.
  fields as cbass_isc_Isam62a_a53_512kb_wrap_main_0_a53_quad_wrap_cba_axi_r_isc_region_0_control
0x4410 cbass_isc_Iusb2ss_16ffc_main_0_mstr0_isc_region_0_start_address_l — The ISC Region 0 Start Address Low Register defines the start address bits 31 to 0 for the master Iusb2ss_16ffc_main_0.mstr0 region 0 ISC.
  fields as cbass_isc_Isam62a_a53_512kb_wrap_main_0_a53_quad_wrap_cba_axi_r_isc_region_0_start_address_l
0x4414 cbass_isc_Iusb2ss_16ffc_main_0_mstr0_isc_region_0_start_address_h — The ISC Region 0 Start Address High Register defines the start address bits 47 to 32 for the master Iusb2ss_16ffc_main_0.mstr0 region 0 ISC.
  fields as cbass_isc_Isam62a_a53_512kb_wrap_main_0_a53_quad_wrap_cba_axi_r_isc_region_0_start_address_h
0x4418 cbass_isc_Iusb2ss_16ffc_main_0_mstr0_isc_region_0_end_address_l access per field reset 0xFFF — The ISC Region 0 End Address Low Register defines the end included address bits 31 to 0 for the master Iusb2ss_16ffc_main_0.mstr0 region 0 ISC.
  fields as cbass_isc_Isam62a_a53_512kb_wrap_main_0_a53_quad_wrap_cba_axi_r_isc_region_0_end_address_l
0x441C cbass_isc_Iusb2ss_16ffc_main_0_mstr0_isc_region_0_end_address_h — The ISC Region 0 End Address High Register defines the end address bits 47 to 32 for the master Iusb2ss_16ffc_main_0.mstr0 region 0 ISC.
  fields as cbass_isc_Isam62a_a53_512kb_wrap_main_0_a53_quad_wrap_cba_axi_r_isc_region_0_end_address_h
0x4420 cbass_isc_Iusb2ss_16ffc_main_0_mstr0_isc_region_def_control access not given reset 0x109B4A — The ISC Default Region Control Register defines the control fields for the master Iusb2ss_16ffc_main_0.mstr0 region 1 ISC.
  fields as cbass_isc_Isam62a_a53_512kb_wrap_main_0_a53_quad_wrap_cba_axi_r_isc_region_def_control
0x4800 cbass_isc_Iusb2ss_16ffc_main_1_mstr0_isc_region_0_control access not given reset 0x109C00 — The ISC Region 0 Control Register defines the control fields for the master Iusb2ss_16ffc_main_1.mstr0 region 0 ISC.
  fields as cbass_isc_Isam62a_a53_512kb_wrap_main_0_a53_quad_wrap_cba_axi_r_isc_region_0_control
0x4810 cbass_isc_Iusb2ss_16ffc_main_1_mstr0_isc_region_0_start_address_l — The ISC Region 0 Start Address Low Register defines the start address bits 31 to 0 for the master Iusb2ss_16ffc_main_1.mstr0 region 0 ISC.
  fields as cbass_isc_Isam62a_a53_512kb_wrap_main_0_a53_quad_wrap_cba_axi_r_isc_region_0_start_address_l
0x4814 cbass_isc_Iusb2ss_16ffc_main_1_mstr0_isc_region_0_start_address_h — The ISC Region 0 Start Address High Register defines the start address bits 47 to 32 for the master Iusb2ss_16ffc_main_1.mstr0 region 0 ISC.
  fields as cbass_isc_Isam62a_a53_512kb_wrap_main_0_a53_quad_wrap_cba_axi_r_isc_region_0_start_address_h
0x4818 cbass_isc_Iusb2ss_16ffc_main_1_mstr0_isc_region_0_end_address_l access per field reset 0xFFF — The ISC Region 0 End Address Low Register defines the end included address bits 31 to 0 for the master Iusb2ss_16ffc_main_1.mstr0 region 0 ISC.
  fields as cbass_isc_Isam62a_a53_512kb_wrap_main_0_a53_quad_wrap_cba_axi_r_isc_region_0_end_address_l
0x481C cbass_isc_Iusb2ss_16ffc_main_1_mstr0_isc_region_0_end_address_h — The ISC Region 0 End Address High Register defines the end address bits 47 to 32 for the master Iusb2ss_16ffc_main_1.mstr0 region 0 ISC.
  fields as cbass_isc_Isam62a_a53_512kb_wrap_main_0_a53_quad_wrap_cba_axi_r_isc_region_0_end_address_h
